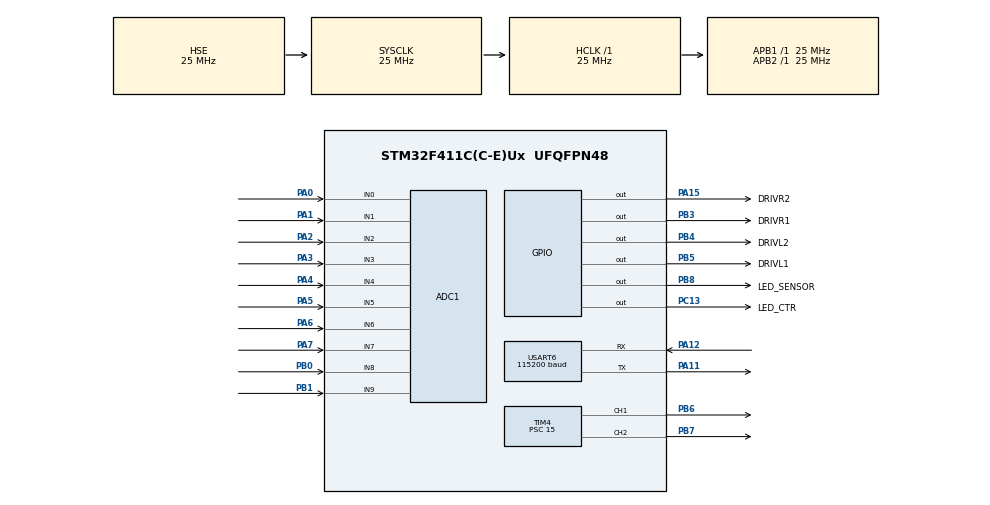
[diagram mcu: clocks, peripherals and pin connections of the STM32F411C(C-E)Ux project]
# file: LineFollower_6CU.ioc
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ADC1.Channel-1\#ChannelRegularConversion=ADC_CHANNEL_0
ADC1.Channel-10\#ChannelRegularConversion=ADC_CHANNEL_9
ADC1.Channel-2\#ChannelRegularConversion=ADC_CHANNEL_1
ADC1.Channel-3\#ChannelRegularConversion=ADC_CHANNEL_2
ADC1.Channel-4\#ChannelRegularConversion=ADC_CHANNEL_3
ADC1.Channel-5\#ChannelRegularConversion=ADC_CHANNEL_4
ADC1.Channel-6\#ChannelRegularConversion=ADC_CHANNEL_5
ADC1.Channel-7\#ChannelRegularConversion=ADC_CHANNEL_6
ADC1.Channel-8\#ChannelRegularConversion=ADC_CHANNEL_7
ADC1.Channel-9\#ChannelRegularConversion=ADC_CHANNEL_8
ADC1.NbrOfConversion=10
ADC1.NbrOfConversionFlag=1
ADC1.Rank-1\#ChannelRegularConversion=1
ADC1.Rank-10\#ChannelRegularConversion=10
ADC1.Rank-2\#ChannelRegularConversion=2
ADC1.Rank-3\#ChannelRegularConversion=3
ADC1.Rank-4\#ChannelRegularConversion=4
ADC1.Rank-5\#ChannelRegularConversion=5
ADC1.Rank-6\#ChannelRegularConversion=6
ADC1.Rank-7\#ChannelRegularConversion=7
ADC1.Rank-8\#ChannelRegularConversion=8
ADC1.Rank-9\#ChannelRegularConversion=9
ADC1.SamplingTime-1\#ChannelRegularConversion=ADC_SAMPLETIME_112CYCLES
ADC1.SamplingTime-10\#ChannelRegularConversion=ADC_SAMPLETIME_112CYCLES
ADC1.SamplingTime-2\#ChannelRegularConversion=ADC_SAMPLETIME_112CYCLES
ADC1.SamplingTime-3\#ChannelRegularConversion=ADC_SAMPLETIME_112CYCLES
ADC1.SamplingTime-4\#ChannelRegularConversion=ADC_SAMPLETIME_112CYCLES
ADC1.SamplingTime-5\#ChannelRegularConversion=ADC_SAMPLETIME_112CYCLES
ADC1.SamplingTime-6\#ChannelRegularConversion=ADC_SAMPLETIME_112CYCLES
ADC1.SamplingTime-7\#ChannelRegularConversion=ADC_SAMPLETIME_112CYCLES
ADC1.SamplingTime-8\#ChannelRegularConversion=ADC_SAMPLETIME_112CYCLES
ADC1.SamplingTime-9\#ChannelRegularConversion=ADC_SAMPLETIME_112CYCLES
ADC1.master=1
FREERTOS.BinarySemaphores01=CommSemaphore,Dynamic,NULL
FREERTOS.Tasks01=driveTask,0,1024,StartDriveTask,Default,NULL,Dynamic,NULL,NULL;commTask,0,1024,StartCommTask,Default,NULL,Dynamic,NULL,NULL
Mcu.Family=STM32F4
Mcu.Name=STM32F411C(C-E)Ux
Mcu.Package=UFQFPN48
NVIC.PriorityGroup=NVIC_PRIORITYGROUP_4
NVIC.TIM1_UP_TIM10_IRQn=true\:15\:0\:false\:false\:true\:false\:false\:true\:true
NVIC.TIM4_IRQn=true\:10\:0\:true\:false\:true\:true\:true\:true\:true
NVIC.TimeBase=TIM1_UP_TIM10_IRQn
NVIC.TimeBaseIP=TIM10
NVIC.USART6_IRQn=true\:5\:0\:false\:false\:true\:true\:true\:true\:true
PA0-WKUP.Signal=ADCx_IN0
PA1.Signal=ADCx_IN1
PA11.Mode=Asynchronous
PA11.Signal=USART6_TX
PA12.Mode=Asynchronous
PA12.Signal=USART6_RX
PA13.Mode=Serial_Wire
PA13.Signal=SYS_JTMS-SWDIO
PA14.Mode=Serial_Wire
PA14.Signal=SYS_JTCK-SWCLK
PA15.GPIO_Label=DRIVR2
PA15.Signal=GPIO_Output
PA2.Signal=ADCx_IN2
PA3.Signal=ADCx_IN3
PA4.Signal=ADCx_IN4
PA5.Signal=ADCx_IN5
PA6.Signal=ADCx_IN6
PA7.Signal=ADCx_IN7
PB0.Signal=ADCx_IN8
PB1.Signal=ADCx_IN9
PB3.GPIO_Label=DRIVR1
PB3.Signal=GPIO_Output
PB4.GPIO_Label=DRIVL2
PB4.Signal=GPIO_Output
PB5.GPIO_Label=DRIVL1
PB5.Signal=GPIO_Output
PB6.Signal=S_TIM4_CH1
PB7.Signal=S_TIM4_CH2
PB8.GPIO_Label=LED_SENSOR
PB8.Signal=GPIO_Output
PC13-ANTI_TAMP.GPIO_Label=LED_CTR
PC13-ANTI_TAMP.GPIO_PuPd=GPIO_PULLUP
PC13-ANTI_TAMP.Signal=GPIO_Output
PH0\ -\ OSC_IN.Mode=HSE-External-Oscillator
PH0\ -\ OSC_IN.Signal=RCC_OSC_IN
PH1\ -\ OSC_OUT.Mode=HSE-External-Oscillator
PH1\ -\ OSC_OUT.Signal=RCC_OSC_OUT
ProjectManager.HeapSize=0x200
ProjectManager.StackSize=0x400
ProjectManager.TargetToolchain=Makefile
RCC.48MHZClocksFreq_Value=75000000
RCC.AHBFreq_Value=25000000
RCC.APB1Freq_Value=25000000
RCC.APB1TimFreq_Value=25000000
RCC.APB2Freq_Value=25000000
RCC.APB2TimFreq_Value=25000000
RCC.CortexFreq_Value=25000000
RCC.HCLKFreq_Value=25000000
RCC.HSE_VALUE=25000000
RCC.HSI_VALUE=16000000
RCC.LSE_VALUE=32768
RCC.PLLSourceVirtual=RCC_PLLSOURCE_HSE
RCC.SYSCLKFreq_VALUE=25000000
RCC.SYSCLKSource=RCC_SYSCLKSOURCE_HSE
RCC.VCOOutputFreq_Value=300000000
SH.ADCx_IN0.0=ADC1_IN0,IN0
SH.ADCx_IN1.0=ADC1_IN1,IN1
SH.ADCx_IN2.0=ADC1_IN2,IN2
SH.ADCx_IN3.0=ADC1_IN3,IN3
SH.ADCx_IN4.0=ADC1_IN4,IN4
SH.ADCx_IN5.0=ADC1_IN5,IN5
SH.ADCx_IN6.0=ADC1_IN6,IN6
SH.ADCx_IN7.0=ADC1_IN7,IN7
SH.ADCx_IN8.0=ADC1_IN8,IN8
SH.ADCx_IN9.0=ADC1_IN9,IN9
SH.S_TIM4_CH1.0=TIM4_CH1,PWM Generation1 CH1
SH.S_TIM4_CH2.0=TIM4_CH2,PWM Generation2 CH2
TIM4.AutoReloadPreload=TIM_AUTORELOAD_PRELOAD_ENABLE
TIM4.Channel-PWM\ Generation1\ CH1=TIM_CHANNEL_1
TIM4.Channel-PWM\ Generation2\ CH2=TIM_CHANNEL_2
TIM4.Period=19
TIM4.Prescaler=15
USART6.BaudRate=115200
USART6.VirtualMode=VM_ASYNC
VP_FREERTOS_VS_CMSIS_V1.Mode=CMSIS_V1
VP_SYS_VS_tim10.Mode=TIM10
board=custom

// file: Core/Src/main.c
/* USER CODE BEGIN Header */
/**
  ******************************************************************************
  * @file           : main.c
  * @brief          : Main program body
  ******************************************************************************
  * @attention
  *
  * Copyright (c) 2023 STMicroelectronics.
  * All rights reserved.
  *
  * This software is licensed under terms that can be found in the LICENSE file
  * in the root directory of this software component.
  * If no LICENSE file comes with this software, it is provided AS-IS.
  *
  ******************************************************************************
  */
/* USER CODE END Header */
#include "cmsis_os.h"
#include "adc.h"
#include "tim.h"
#include "usart.h"
#include "gpio.h"
#include "main.h"

void SystemClock_Config(void);
void MX_FREERTOS_Init(void);

int main(void)
{

  /* MCU Configuration--------------------------------------------------------*/

  /* Reset of all peripherals, Initializes the Flash interface and the Systick. */
  HAL_Init();

  /* Configure the system clock */
  SystemClock_Config();

  /* Initialize all configured peripherals */
  MX_GPIO_Init();
  MX_ADC1_Init();
  MX_TIM4_Init();
  MX_USART6_UART_Init();

  /* Call init function for freertos objects (in freertos.c) */
  MX_FREERTOS_Init();

  /* Start scheduler */
  osKernelStart();
  /* We should never get here as control is now taken by the scheduler */
  /* Infinite loop */
  while (1)
  {

  }
}

void SystemClock_Config(void)
{
  RCC_OscInitTypeDef RCC_OscInitStruct = {0};
  RCC_ClkInitTypeDef RCC_ClkInitStruct = {0};

  /** Configure the main internal regulator output voltage
  */
  __HAL_RCC_PWR_CLK_ENABLE();
  __HAL_PWR_VOLTAGESCALING_CONFIG(PWR_REGULATOR_VOLTAGE_SCALE1);

  /** Initializes the RCC Oscillators according to the specified parameters
  * in the RCC_OscInitTypeDef structure.
  */
  RCC_OscInitStruct.OscillatorType = RCC_OSCILLATORTYPE_HSE;
  RCC_OscInitStruct.HSEState = RCC_HSE_ON;
  RCC_OscInitStruct.PLL.PLLState = RCC_PLL_NONE;
  if (HAL_RCC_OscConfig(&RCC_OscInitStruct) != HAL_OK)
  {
    Error_Handler();
  }

  /** Initializes the CPU, AHB and APB buses clocks
  */
  RCC_ClkInitStruct.ClockType = RCC_CLOCKTYPE_HCLK|RCC_CLOCKTYPE_SYSCLK
                              |RCC_CLOCKTYPE_PCLK1|RCC_CLOCKTYPE_PCLK2;
  RCC_ClkInitStruct.SYSCLKSource = RCC_SYSCLKSOURCE_HSE;
  RCC_ClkInitStruct.AHBCLKDivider = RCC_SYSCLK_DIV1;
  RCC_ClkInitStruct.APB1CLKDivider = RCC_HCLK_DIV1;
  RCC_ClkInitStruct.APB2CLKDivider = RCC_HCLK_DIV1;

  if (HAL_RCC_ClockConfig(&RCC_ClkInitStruct, FLASH_LATENCY_0) != HAL_OK)
  {
    Error_Handler();
  }
}

void HAL_TIM_PeriodElapsedCallback(TIM_HandleTypeDef *htim)
{
  if (htim->Instance == TIM10) {
    HAL_IncTick();
  }
}

void Error_Handler(void)
{
  __disable_irq();
  while (1)
  {
  }
}

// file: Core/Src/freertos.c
/* USER CODE BEGIN Header */
/**
  ******************************************************************************
  * File Name          : freertos.c
  * Description        : Code for freertos applications
  ******************************************************************************
  * @attention
  *
  * Copyright (c) 2023 STMicroelectronics.
  * All rights reserved.
  *
  * This software is licensed under terms that can be found in the LICENSE file
  * in the root directory of this software component.
  * If no LICENSE file comes with this software, it is provided AS-IS.
  *
  ******************************************************************************
  */
/* USER CODE END Header */

#include "FreeRTOS.h"
#include "task.h"
#include "main.h"
#include "cmsis_os.h"

/* USER CODE BEGIN Includes */
#include "driver.c"
#include "comm.c"
/* USER CODE END Includes */

osThreadId driveTaskHandle;
osThreadId commTaskHandle;
osSemaphoreId CommSemaphoreHandle;

void StartDriveTask(void const * argument);
void StartCommTask(void const * argument);

void MX_FREERTOS_Init(void); /* (MISRA C 2004 rule 8.1) */

/* GetIdleTaskMemory prototype (linked to static allocation support) */
void vApplicationGetIdleTaskMemory( StaticTask_t **ppxIdleTaskTCBBuffer, StackType_t **ppxIdleTaskStackBuffer, uint32_t *pulIdleTaskStackSize );

/* USER CODE BEGIN GET_IDLE_TASK_MEMORY */
static StaticTask_t xIdleTaskTCBBuffer;
static StackType_t xIdleStack[configMINIMAL_STACK_SIZE];

void vApplicationGetIdleTaskMemory( StaticTask_t **ppxIdleTaskTCBBuffer, StackType_t **ppxIdleTaskStackBuffer, uint32_t *pulIdleTaskStackSize )
{
  *ppxIdleTaskTCBBuffer = &xIdleTaskTCBBuffer;
  *ppxIdleTaskStackBuffer = &xIdleStack[0];
  *pulIdleTaskStackSize = configMINIMAL_STACK_SIZE;
  /* place for user code */
}
/* USER CODE END GET_IDLE_TASK_MEMORY */

void MX_FREERTOS_Init(void) {

  /* Create the semaphores(s) */
  /* definition and creation of CommSemaphore */
  osSemaphoreDef(CommSemaphore);
  CommSemaphoreHandle = osSemaphoreCreate(osSemaphore(CommSemaphore), 1);

  /* Create the thread(s) */
  /* definition and creation of driveTask */
  osThreadDef(driveTask, StartDriveTask, osPriorityNormal, 0, 1024);
  driveTaskHandle = osThreadCreate(osThread(driveTask), NULL);

  /* definition and creation of commTask */
  osThreadDef(commTask, StartCommTask, osPriorityNormal, 0, 1024);
  commTaskHandle = osThreadCreate(osThread(commTask), NULL);

}

void StartDriveTask(void const * argument)
{
  /* USER CODE BEGIN StartDriveTask */
  /* Infinite loop */
  ExStartDriveTask(argument);
  /* USER CODE END StartDriveTask */
}

void StartCommTask(void const * argument)
{
  /* USER CODE BEGIN StartCommTask */
  /* Infinite loop */
  ExStartCommTask(argument);
  /* USER CODE END StartCommTask */
}
